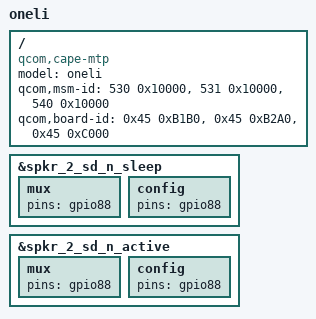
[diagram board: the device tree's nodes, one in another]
/dts-v1/;
/plugin/;

#include "cape-audio-moto-oneli-common.dtsi"

 / {
	model = "oneli";
	compatible = "qcom,cape-mtp", "qcom,cape", "qcom,mtp", "moto,oenli";
	qcom,msm-id = <530 0x10000>, <531 0x10000>, <540 0x10000>;
	qcom,board-id = <0x45 0xB1B0>, <0x45 0xB2A0>, <0x45 0xC000>;
};

&spkr_2_sd_n_sleep {
	mux {
		pins = "gpio88";
	};
	config {
		pins = "gpio88";
	};
};

&spkr_2_sd_n_active {
	mux {
		pins = "gpio88";
	};

	config {
		pins = "gpio88";
	};
};
